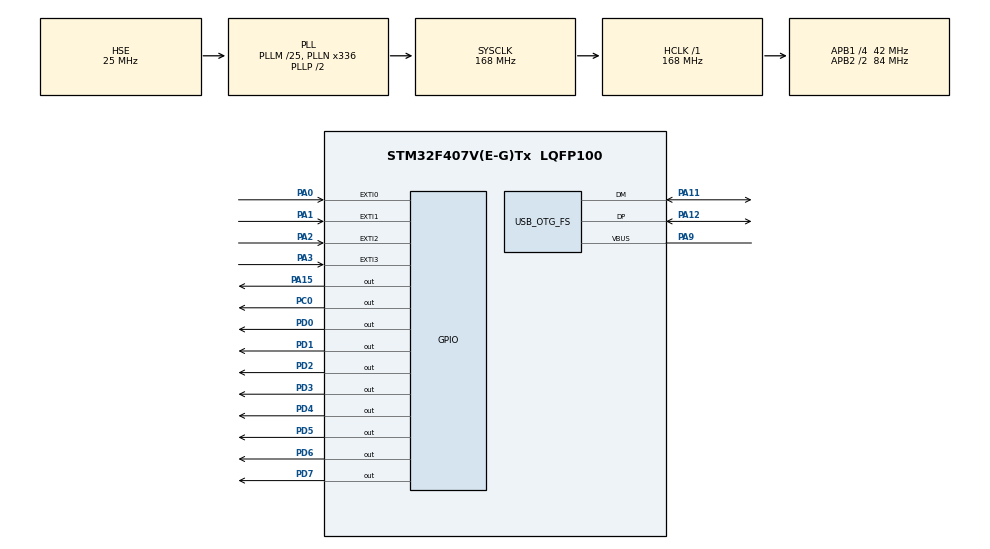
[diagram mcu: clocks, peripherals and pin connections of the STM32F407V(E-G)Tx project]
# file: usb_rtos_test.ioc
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FREERTOS.Tasks01=defaultTask,-3,128,StartDefaultTask,Default,NULL,Dynamic,NULL,NULL;usbTask,1,128,usbOSfunc,Default,NULL,Dynamic,NULL,NULL
FREERTOS.configGENERATE_RUN_TIME_STATS=1
FREERTOS.configUSE_MUTEXES=0
Mcu.Family=STM32F4
Mcu.Name=STM32F407V(E-G)Tx
Mcu.Package=LQFP100
NVIC.EXTI0_IRQn=true\:5\:0\:false\:false\:true\:false\:true\:true
NVIC.EXTI1_IRQn=true\:5\:0\:false\:false\:true\:false\:true\:true
NVIC.EXTI2_IRQn=true\:5\:0\:false\:false\:true\:false\:true\:true
NVIC.EXTI3_IRQn=true\:5\:0\:false\:false\:true\:false\:true\:true
NVIC.OTG_FS_IRQn=true\:5\:0\:false\:false\:true\:true\:false\:true
NVIC.PriorityGroup=NVIC_PRIORITYGROUP_4
NVIC.TIM6_DAC_IRQn=true\:0\:0\:false\:false\:true\:false\:false\:true
NVIC.TimeBase=TIM6_DAC_IRQn
NVIC.TimeBaseIP=TIM6
PA0-WKUP.Signal=GPXTI0
PA1.Signal=GPXTI1
PA11.Mode=Host_Only
PA11.Signal=USB_OTG_FS_DM
PA12.Mode=Host_Only
PA12.Signal=USB_OTG_FS_DP
PA13.Mode=Trace_Asynchronous_SW
PA13.Signal=SYS_JTMS-SWDIO
PA14.Mode=Trace_Asynchronous_SW
PA14.Signal=SYS_JTCK-SWCLK
PA15.Signal=GPIO_Output
PA2.Signal=GPXTI2
PA3.Signal=GPXTI3
PA9.Mode=Activate_VBUS
PA9.Signal=USB_OTG_FS_VBUS
PB3.Mode=Trace_Asynchronous_SW
PB3.Signal=SYS_JTDO-SWO
PC0.Signal=GPIO_Output
PC14-OSC32_IN.Mode=LSE-External-Oscillator
PC14-OSC32_IN.Signal=RCC_OSC32_IN
PC15-OSC32_OUT.Mode=LSE-External-Oscillator
PC15-OSC32_OUT.Signal=RCC_OSC32_OUT
PD0.Signal=GPIO_Output
PD1.Signal=GPIO_Output
PD2.Signal=GPIO_Output
PD3.Signal=GPIO_Output
PD4.Signal=GPIO_Output
PD5.Signal=GPIO_Output
PD6.Signal=GPIO_Output
PD7.Signal=GPIO_Output
PH0-OSC_IN.Mode=HSE-External-Oscillator
PH0-OSC_IN.Signal=RCC_OSC_IN
PH1-OSC_OUT.Mode=HSE-External-Oscillator
PH1-OSC_OUT.Signal=RCC_OSC_OUT
ProjectManager.HeapSize=0x200
ProjectManager.StackSize=0x400
ProjectManager.TargetToolchain=STM32CubeIDE
RCC.48MHZClocksFreq_Value=48000000
RCC.AHBFreq_Value=168000000
RCC.APB1CLKDivider=RCC_HCLK_DIV4
RCC.APB1Freq_Value=42000000
RCC.APB1TimFreq_Value=84000000
RCC.APB2CLKDivider=RCC_HCLK_DIV2
RCC.APB2Freq_Value=84000000
RCC.APB2TimFreq_Value=168000000
RCC.CortexFreq_Value=168000000
RCC.HCLKFreq_Value=168000000
RCC.HSE_VALUE=25000000
RCC.HSI_VALUE=16000000
RCC.PLLM=25
RCC.PLLN=336
RCC.PLLQ=7
RCC.SYSCLKFreq_VALUE=168000000
RCC.SYSCLKSource=RCC_SYSCLKSOURCE_PLLCLK
RCC.VCOOutputFreq_Value=336000000
USB_HOST.BSP.number=1
USB_HOST.USBH_HandleTypeDef-MSC_FS=hUsbHostFS
USB_HOST.USBH_PROCESS_PRIO-MSC_FS=osPriorityNormal
USB_HOST.VirtualModeFS=Msc
USB_HOST0.BSP.STBoard=false
USB_HOST0.BSP.api=Unknown
USB_HOST0.BSP.i2caddr=0
USB_HOST0.BSP.instance=PA15
USB_HOST0.BSP.ip=GPIO
USB_HOST0.BSP.mode=Output
USB_HOST0.BSP.name=Drive_VBUS_FS
USB_HOST0.BSP.solution=PA15
USB_OTG_FS.VirtualMode=Host_Only
USB_OTG_FS.phy_itface=HCD_PHY_EMBEDDED
VP_FATFS_VS_USB.Mode=USB
VP_FREERTOS_VS_CMSIS_V1.Mode=CMSIS_V1
VP_SYS_VS_tim6.Mode=TIM6
VP_USB_HOST_VS_USB_HOST_MSC_FS.Mode=MSC_FS
board=STM32F407G-DISC1

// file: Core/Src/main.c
/* USER CODE BEGIN Header */
/**
  ******************************************************************************
  * @file           : main.c
  * @brief          : Main program body
  ******************************************************************************
  * @attention
  *
  * <h2><center>&copy; Copyright (c) 2021 STMicroelectronics.
  * All rights reserved.</center></h2>
  *
  * This software component is licensed by ST under BSD 3-Clause license,
  * the "License"; You may not use this file except in compliance with the
  * License. You may obtain a copy of the License at:
  *                        opensource.org/licenses/BSD-3-Clause
  *
  ******************************************************************************
  */
/* USER CODE END Header */
#include "main.h"
#include "cmsis_os.h"
#include "fatfs.h"
#include "usb_host.h"

/* USER CODE BEGIN Includes */
#include "usbh_def.h"
/* USER CODE END Includes */

osThreadId defaultTaskHandle;
osThreadId usbTaskHandle;
/* USER CODE BEGIN PV */
extern USBH_HandleTypeDef hUsbHostFS;
/* USER CODE END PV */

void SystemClock_Config(void);
static void MX_GPIO_Init(void);
void StartDefaultTask(void const * argument);
void usbOSfunc(void const * argument);

int main(void)
{

  /* MCU Configuration--------------------------------------------------------*/

  /* Reset of all peripherals, Initializes the Flash interface and the Systick. */
  HAL_Init();

  /* Configure the system clock */
  SystemClock_Config();

  /* Initialize all configured peripherals */
  MX_GPIO_Init();
  MX_FATFS_Init();

  /* Create the thread(s) */
  /* definition and creation of defaultTask */
  osThreadDef(defaultTask, StartDefaultTask, osPriorityIdle, 0, 128);
  defaultTaskHandle = osThreadCreate(osThread(defaultTask), NULL);

  /* definition and creation of usbTask */
  osThreadDef(usbTask, usbOSfunc, osPriorityAboveNormal, 0, 128);
  usbTaskHandle = osThreadCreate(osThread(usbTask), NULL);

  /* Start scheduler */
  osKernelStart();

  /* We should never get here as control is now taken by the scheduler */
  /* Infinite loop */
  while (1)
  {

  }
}

void SystemClock_Config(void)
{
  RCC_OscInitTypeDef RCC_OscInitStruct = {0};
  RCC_ClkInitTypeDef RCC_ClkInitStruct = {0};

  /** Configure the main internal regulator output voltage
  */
  __HAL_RCC_PWR_CLK_ENABLE();
  __HAL_PWR_VOLTAGESCALING_CONFIG(PWR_REGULATOR_VOLTAGE_SCALE1);
  /** Initializes the RCC Oscillators according to the specified parameters
  * in the RCC_OscInitTypeDef structure.
  */
  RCC_OscInitStruct.OscillatorType = RCC_OSCILLATORTYPE_HSE;
  RCC_OscInitStruct.HSEState = RCC_HSE_ON;
  RCC_OscInitStruct.PLL.PLLState = RCC_PLL_ON;
  RCC_OscInitStruct.PLL.PLLSource = RCC_PLLSOURCE_HSE;
  RCC_OscInitStruct.PLL.PLLM = 25;
  RCC_OscInitStruct.PLL.PLLN = 336;
  RCC_OscInitStruct.PLL.PLLP = RCC_PLLP_DIV2;
  RCC_OscInitStruct.PLL.PLLQ = 7;
  if (HAL_RCC_OscConfig(&RCC_OscInitStruct) != HAL_OK)
  {
    Error_Handler();
  }
  /** Initializes the CPU, AHB and APB buses clocks
  */
  RCC_ClkInitStruct.ClockType = RCC_CLOCKTYPE_HCLK|RCC_CLOCKTYPE_SYSCLK
                              |RCC_CLOCKTYPE_PCLK1|RCC_CLOCKTYPE_PCLK2;
  RCC_ClkInitStruct.SYSCLKSource = RCC_SYSCLKSOURCE_PLLCLK;
  RCC_ClkInitStruct.AHBCLKDivider = RCC_SYSCLK_DIV1;
  RCC_ClkInitStruct.APB1CLKDivider = RCC_HCLK_DIV4;
  RCC_ClkInitStruct.APB2CLKDivider = RCC_HCLK_DIV2;

  if (HAL_RCC_ClockConfig(&RCC_ClkInitStruct, FLASH_LATENCY_5) != HAL_OK)
  {
    Error_Handler();
  }
}

static void MX_GPIO_Init(void)
{
  GPIO_InitTypeDef GPIO_InitStruct = {0};

  /* GPIO Ports Clock Enable */
  __HAL_RCC_GPIOC_CLK_ENABLE();
  __HAL_RCC_GPIOH_CLK_ENABLE();
  __HAL_RCC_GPIOA_CLK_ENABLE();
  __HAL_RCC_GPIOD_CLK_ENABLE();
  __HAL_RCC_GPIOB_CLK_ENABLE();

  /*Configure GPIO pin Output Level */
  HAL_GPIO_WritePin(GPIOC, GPIO_PIN_0, GPIO_PIN_RESET);

  /*Configure GPIO pin Output Level */
  HAL_GPIO_WritePin(GPIOA, GPIO_PIN_15, GPIO_PIN_RESET);

  /*Configure GPIO pin Output Level */
  HAL_GPIO_WritePin(GPIOD, GPIO_PIN_0|GPIO_PIN_1|GPIO_PIN_2|GPIO_PIN_3
                          |GPIO_PIN_4|GPIO_PIN_5|GPIO_PIN_6|GPIO_PIN_7, GPIO_PIN_RESET);

  /*Configure GPIO pin : PC0 */
  GPIO_InitStruct.Pin = GPIO_PIN_0;
  GPIO_InitStruct.Mode = GPIO_MODE_OUTPUT_PP;
  GPIO_InitStruct.Pull = GPIO_NOPULL;
  GPIO_InitStruct.Speed = GPIO_SPEED_FREQ_LOW;
  HAL_GPIO_Init(GPIOC, &GPIO_InitStruct);

  /*Configure GPIO pins : PA0 PA1 PA2 PA3 */
  GPIO_InitStruct.Pin = GPIO_PIN_0|GPIO_PIN_1|GPIO_PIN_2|GPIO_PIN_3;
  GPIO_InitStruct.Mode = GPIO_MODE_IT_RISING;
  GPIO_InitStruct.Pull = GPIO_NOPULL;
  HAL_GPIO_Init(GPIOA, &GPIO_InitStruct);

  /*Configure GPIO pin : PA15 */
  GPIO_InitStruct.Pin = GPIO_PIN_15;
  GPIO_InitStruct.Mode = GPIO_MODE_OUTPUT_PP;
  GPIO_InitStruct.Pull = GPIO_NOPULL;
  GPIO_InitStruct.Speed = GPIO_SPEED_FREQ_LOW;
  HAL_GPIO_Init(GPIOA, &GPIO_InitStruct);

  /*Configure GPIO pins : PD0 PD1 PD2 PD3
                           PD4 PD5 PD6 PD7 */
  GPIO_InitStruct.Pin = GPIO_PIN_0|GPIO_PIN_1|GPIO_PIN_2|GPIO_PIN_3
                          |GPIO_PIN_4|GPIO_PIN_5|GPIO_PIN_6|GPIO_PIN_7;
  GPIO_InitStruct.Mode = GPIO_MODE_OUTPUT_PP;
  GPIO_InitStruct.Pull = GPIO_NOPULL;
  GPIO_InitStruct.Speed = GPIO_SPEED_FREQ_LOW;
  HAL_GPIO_Init(GPIOD, &GPIO_InitStruct);

  /* EXTI interrupt init*/
  HAL_NVIC_SetPriority(EXTI0_IRQn, 5, 0);
  HAL_NVIC_EnableIRQ(EXTI0_IRQn);

  HAL_NVIC_SetPriority(EXTI1_IRQn, 5, 0);
  HAL_NVIC_EnableIRQ(EXTI1_IRQn);

  HAL_NVIC_SetPriority(EXTI2_IRQn, 5, 0);
  HAL_NVIC_EnableIRQ(EXTI2_IRQn);

  HAL_NVIC_SetPriority(EXTI3_IRQn, 5, 0);
  HAL_NVIC_EnableIRQ(EXTI3_IRQn);

}

void StartDefaultTask(void const * argument)
{
  /* init code for USB_HOST */
  MX_USB_HOST_Init();
  /* USER CODE BEGIN 5 */
  USBH_OSEventTypeDef startMsg = (uint32_t) USBH_PORT_EVENT;
  osMessagePut(hUsbHostFS.os_event, startMsg, 0U);
  /* Infinite loop */
  for(;;)
  {
    osDelay(1);
  }
  /* USER CODE END 5 */
}

void usbOSfunc(void const * argument)
{
  /* USER CODE BEGIN usbOSfunc */
	//static offset variable
	//number of bytes to read
	osDelay(1000);	//delayed start of file reading
  /* Infinite loop */
  for(;;)
  {
	  //read_file
	  //increment the offset value
	  //seek file
	  osDelay(500);
  }
  /* USER CODE END usbOSfunc */
}

 /**
  * @brief  Period elapsed callback in non blocking mode
  * @note   This function is called  when TIM6 interrupt took place, inside
  * HAL_TIM_IRQHandler(). It makes a direct call to HAL_IncTick() to increment
  * a global variable "uwTick" used as application time base.
  * @param  htim : TIM handle
  * @retval None
  */
void HAL_TIM_PeriodElapsedCallback(TIM_HandleTypeDef *htim)
{
  if (htim->Instance == TIM6) {
    HAL_IncTick();
  }
}

void Error_Handler(void)
{
  __disable_irq();
  while (1)
  {
  }
}

/************************ (C) COPYRIGHT STMicroelectronics *****END OF FILE****/
